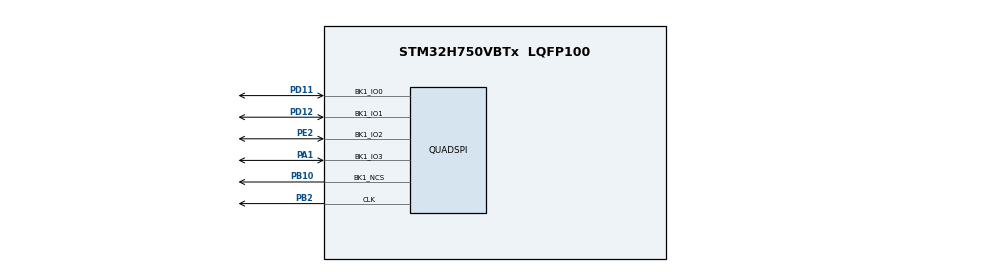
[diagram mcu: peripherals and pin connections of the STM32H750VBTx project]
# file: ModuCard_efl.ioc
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CORTEX_M7.CPU_DCache=Enabled
CORTEX_M7.CPU_ICache=Enabled
CORTEX_M7.Enable_S-Cortex_Memory_Protection_Unit_Region1_Settings_S=__NULL
CORTEX_M7.MPU_Control=__NULL
CORTEX_M7.default_mode_Activation=1
Mcu.Family=STM32H7
Mcu.Name=STM32H750VBTx
Mcu.Package=LQFP100
NVIC.PriorityGroup=NVIC_PRIORITYGROUP_4
NVIC.TIM7_IRQn=true\:15\:0\:false\:false\:true\:false\:true\:true
NVIC.TimeBase=TIM7_IRQn
NVIC.TimeBaseIP=TIM7
PA1.Mode=Single Bank 1
PA1.Signal=QUADSPI_BK1_IO3
PA13\ (JTMS/SWDIO).Mode=Serial_Wire
PA13\ (JTMS/SWDIO).Signal=DEBUG_JTMS-SWDIO
PA14\ (JTCK/SWCLK).Mode=Serial_Wire
PA14\ (JTCK/SWCLK).Signal=DEBUG_JTCK-SWCLK
PB10.Mode=Single Bank 1
PB10.Signal=QUADSPI_BK1_NCS
PB2.Mode=Single Bank 1
PB2.Signal=QUADSPI_CLK
PC14-OSC32_IN\ (OSC32_IN).Mode=LSE-External-Oscillator
PC14-OSC32_IN\ (OSC32_IN).Signal=RCC_OSC32_IN
PC15-OSC32_OUT\ (OSC32_OUT).Mode=LSE-External-Oscillator
PC15-OSC32_OUT\ (OSC32_OUT).Signal=RCC_OSC32_OUT
PD11.Mode=Single Bank 1
PD11.Signal=QUADSPI_BK1_IO0
PD12.Mode=Single Bank 1
PD12.Signal=QUADSPI_BK1_IO1
PE2.Mode=Single Bank 1
PE2.Signal=QUADSPI_BK1_IO2
PH0-OSC_IN\ (PH0).Mode=HSE-External-Oscillator
PH0-OSC_IN\ (PH0).Signal=RCC_OSC_IN
PH1-OSC_OUT\ (PH1).Mode=HSE-External-Oscillator
PH1-OSC_OUT\ (PH1).Signal=RCC_OSC_OUT
ProjectManager.HeapSize=0xF00
ProjectManager.StackSize=0x900
ProjectManager.TargetToolchain=CMake
QUADSPI.ChipSelectHighTime=QSPI_CS_HIGH_TIME_1_CYCLE
QUADSPI.ClockPrescaler=1
QUADSPI.DeviceType=SPI_DEVICE_FLASH
QUADSPI.FifoThreshold=4
QUADSPI.FlashSize=23
QUADSPI.SampleShifting=QSPI_SAMPLE_SHIFTING_HALFCYCLE
RCC.ADCCLockSelection=RCC_ADCCLKSOURCE_PLL3
RCC.ADCFreq_Value=78000000
RCC.APB1Freq_Value=120000000
RCC.APB2Freq_Value=120000000
RCC.APB3Freq_Value=120000000
RCC.APB4Freq_Value=120000000
RCC.CortexFreq_Value=480000000
RCC.D1PPRE=RCC_APB3_DIV2
RCC.D2PPRE1=RCC_APB1_DIV2
RCC.D2PPRE2=RCC_APB2_DIV2
RCC.D3PPRE=RCC_APB4_DIV2
RCC.DIVM1=2
RCC.DIVM2=1
RCC.DIVM3=1
RCC.DIVN1=160
RCC.DIVN2=13
RCC.DIVN3=13
RCC.DIVP2=10
RCC.DIVQ1=8
RCC.DIVQ2=4
RCC.DIVQ3=3
RCC.HCLKFreq_Value=240000000
RCC.HPRE=RCC_HCLK_DIV2
RCC.HSE_VALUE=12000000
RCC.PLL2FRACN=0
RCC.PLL3FRACN=0
RCC.PLLFRACN=0
RCC.PLLSourceVirtual=RCC_PLLSOURCE_HSE
RCC.QSPICLockSelection=RCC_QSPICLKSOURCE_PLL
RCC.SPI123CLockSelection=RCC_SPI123CLKSOURCE_PLL2
RCC.SYSCLKFreq_VALUE=480000000
RCC.SYSCLKSource=RCC_SYSCLKSOURCE_PLLCLK
RCC.USBCLockSelection=RCC_USBCLKSOURCE_PLL3
RCC.USBFreq_Value=52000000
VP_MEMORYMAP_VS_MEMORYMAP.Mode=CurAppReg
VP_SYS_VS_tim7.Mode=TIM7
board=custom

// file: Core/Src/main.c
/* USER CODE BEGIN Header */
/**
  ******************************************************************************
  * @file           : main.c
  * @brief          : Main program body
  ******************************************************************************
  * @attention
  *
  * Copyright (c) 2025 STMicroelectronics.
  * All rights reserved.
  *
  * This software is licensed under terms that can be found in the LICENSE file
  * in the root directory of this software component.
  * If no LICENSE file comes with this software, it is provided AS-IS.
  *
  ******************************************************************************
  */
/* USER CODE END Header */
#include "main.h"
#include "memorymap.h"
#include "quadspi.h"
#include "gpio.h"
#include <string.h>

#include "w25q_mem.h"

/* USER CODE BEGIN PTD */
#define SECTORS_COUNT 100
/* USER CODE END PTD */

void SystemClock_Config(void);

int main(void)
{

  /* Enable the CPU Cache */

  /* Enable I-Cache---------------------------------------------------------*/
  // SCB_EnableICache();

  /* Enable D-Cache---------------------------------------------------------*/
  // SCB_EnableDCache();

  /* MCU Configuration--------------------------------------------------------*/

  /* Reset of all peripherals, Initializes the Flash interface and the Systick. */
  HAL_Init();

  /* Configure the system clock */
  SystemClock_Config();

  /* Initialize all configured peripherals */
  MX_GPIO_Init();
  MX_QUADSPI_Init();
  uint8_t buffer_test[MEMORY_SECTOR_SIZE] = {0};
  uint32_t var = 0;

  W25Q_STATE state = W25Q_OK;
  state = W25Q_Init();
  state = W25Q_EraseSector(0);
  // make test data
	u8_t byte = 0x65;
	u8_t byte_read = 0;
	u8_t in_page_shift = 0;
	u8_t page_number = 0;
	// write data
	state = W25Q_ProgramByte(byte, in_page_shift, page_number);
	// read data
	state = W25Q_ReadByte(&byte_read, in_page_shift, page_number);

  	//

    HAL_StatusTypeDef ret = HAL_OK;
    uint8_t reg[10] = { 0 };

    if (HAL_QSPI_DeInit(&hqspi) != HAL_OK) {
      return HAL_ERROR;
    }
    MX_QUADSPI_Init();

    QSPI_CommandTypeDef sCommand = { 0 };
    sCommand.InstructionMode = QSPI_INSTRUCTION_1_LINE;
    sCommand.Instruction = READ_STATUS_REG_3_CMD;
    sCommand.AddressMode = QSPI_ADDRESS_NONE;
    sCommand.AlternateByteMode = QSPI_ALTERNATE_BYTES_NONE;
    sCommand.DataMode = QSPI_DATA_1_LINE;
    sCommand.DummyCycles = 0;
    sCommand.DdrMode = QSPI_DDR_MODE_DISABLE;
    sCommand.DdrHoldHalfCycle = QSPI_DDR_HHC_ANALOG_DELAY;
    sCommand.SIOOMode = QSPI_SIOO_INST_EVERY_CMD;
    sCommand.NbData = 1;
    QSPI_WriteEnable();
    // while(true){
      ret = HAL_QSPI_Command(&hqspi,&sCommand,HAL_QPSI_TIMEOUT_DEFAULT_VALUE);
      ret = HAL_QSPI_Receive(&hqspi, reg, HAL_QPSI_TIMEOUT_DEFAULT_VALUE);
    // }
    // CSP_QUADSPI_Init();

    sCommand.Instruction = READ_STATUS_REG_CMD;
    ret = HAL_QSPI_Command(&hqspi,&sCommand,HAL_QPSI_TIMEOUT_DEFAULT_VALUE);
    ret = HAL_QSPI_Receive(&hqspi, reg, HAL_QPSI_TIMEOUT_DEFAULT_VALUE);

    sCommand.Instruction = READ_STATUS_REG_2_CMD;
    ret = HAL_QSPI_Command(&hqspi,&sCommand,HAL_QPSI_TIMEOUT_DEFAULT_VALUE);
    ret = HAL_QSPI_Receive(&hqspi, reg, HAL_QPSI_TIMEOUT_DEFAULT_VALUE);

    sCommand.Instruction = READ_STATUS_REG_3_CMD;
    ret = HAL_QSPI_Command(&hqspi,&sCommand,HAL_QPSI_TIMEOUT_DEFAULT_VALUE);
    ret = HAL_QSPI_Receive(&hqspi, reg, HAL_QPSI_TIMEOUT_DEFAULT_VALUE);

    reg[0] = 0x41;
    reg[1] = 0xF1;
    ret = CSP_QSPI_WriteMemory(reg, 0x00001000, 2);
    ret = CSP_QSPI_Read(buffer_test, 0x00001000, 2);
    if (buffer_test[0] != 0x41 || buffer_test[1] != 0xF1) {
      while (1)
        ; //breakpoint - error detected
    }

  	for (var = 0; var < MEMORY_SECTOR_SIZE; var++) {
  		buffer_test[var] = (var & 0xff);
  	}

  	for (var = 0; var < SECTORS_COUNT; var++) {
      // CSP_QSPI_EraseSector
  		if (CSP_QSPI_EraseSector(var * MEMORY_SECTOR_SIZE,
  				(var + 1) * MEMORY_SECTOR_SIZE - 1) != HAL_OK) {

  			while (1)
  				;  //breakpoint - error detected
  		}

  		if (CSP_QSPI_WriteMemory(buffer_test, var * MEMORY_SECTOR_SIZE,
  				sizeof(buffer_test)) != HAL_OK) {

  			while (1)
  				;  //breakpoint - error detected
  		}

  	}

  	if (CSP_QSPI_EnableMemoryMappedMode() != HAL_OK) {

  		while (1)
  			; //breakpoint - error detected
  	}

  	for (var = 0; var < SECTORS_COUNT; var++) {
      uint8_t *pointer = (uint8_t*) (0x90000000 + var * MEMORY_SECTOR_SIZE);
  		if (memcmp(buffer_test,pointer,MEMORY_SECTOR_SIZE) != HAL_OK) {
  			while (1)
  				;  //breakpoint - error detected - otherwise QSPI works properly
  		}
  	}
  /* USER CODE END 2 */

  /* Infinite loop */
  while (1)
  {

  }
}

void SystemClock_Config(void)
{
  RCC_OscInitTypeDef RCC_OscInitStruct = {0};
  RCC_ClkInitTypeDef RCC_ClkInitStruct = {0};

  /** Supply configuration update enable
  */
  HAL_PWREx_ConfigSupply(PWR_LDO_SUPPLY);

  /** Configure the main internal regulator output voltage
  */
  __HAL_PWR_VOLTAGESCALING_CONFIG(PWR_REGULATOR_VOLTAGE_SCALE0);

  while(!__HAL_PWR_GET_FLAG(PWR_FLAG_VOSRDY)) {}

  /** Initializes the RCC Oscillators according to the specified parameters
  * in the RCC_OscInitTypeDef structure.
  */
  RCC_OscInitStruct.OscillatorType = RCC_OSCILLATORTYPE_HSE;
  RCC_OscInitStruct.HSEState = RCC_HSE_ON;
  RCC_OscInitStruct.PLL.PLLState = RCC_PLL_ON;
  RCC_OscInitStruct.PLL.PLLSource = RCC_PLLSOURCE_HSE;
  RCC_OscInitStruct.PLL.PLLM = 2;
  RCC_OscInitStruct.PLL.PLLN = 160;
  RCC_OscInitStruct.PLL.PLLP = 2;
  RCC_OscInitStruct.PLL.PLLQ = 8;
  RCC_OscInitStruct.PLL.PLLR = 2;
  RCC_OscInitStruct.PLL.PLLRGE = RCC_PLL1VCIRANGE_2;
  RCC_OscInitStruct.PLL.PLLVCOSEL = RCC_PLL1VCOWIDE;
  RCC_OscInitStruct.PLL.PLLFRACN = 0;
  if (HAL_RCC_OscConfig(&RCC_OscInitStruct) != HAL_OK)
  {
    Error_Handler();
  }

  /** Initializes the CPU, AHB and APB buses clocks
  */
  RCC_ClkInitStruct.ClockType = RCC_CLOCKTYPE_HCLK|RCC_CLOCKTYPE_SYSCLK
                              |RCC_CLOCKTYPE_PCLK1|RCC_CLOCKTYPE_PCLK2
                              |RCC_CLOCKTYPE_D3PCLK1|RCC_CLOCKTYPE_D1PCLK1;
  RCC_ClkInitStruct.SYSCLKSource = RCC_SYSCLKSOURCE_PLLCLK;
  RCC_ClkInitStruct.SYSCLKDivider = RCC_SYSCLK_DIV1;
  RCC_ClkInitStruct.AHBCLKDivider = RCC_HCLK_DIV2;
  RCC_ClkInitStruct.APB3CLKDivider = RCC_APB3_DIV2;
  RCC_ClkInitStruct.APB1CLKDivider = RCC_APB1_DIV2;
  RCC_ClkInitStruct.APB2CLKDivider = RCC_APB2_DIV2;
  RCC_ClkInitStruct.APB4CLKDivider = RCC_APB4_DIV2;

  if (HAL_RCC_ClockConfig(&RCC_ClkInitStruct, FLASH_LATENCY_4) != HAL_OK)
  {
    Error_Handler();
  }
}

void HAL_TIM_PeriodElapsedCallback(TIM_HandleTypeDef *htim)
{
  if (htim->Instance == TIM7) {
    HAL_IncTick();
  }
}

void Error_Handler(void)
{
  __disable_irq();
  while (1)
  {
  }
}
